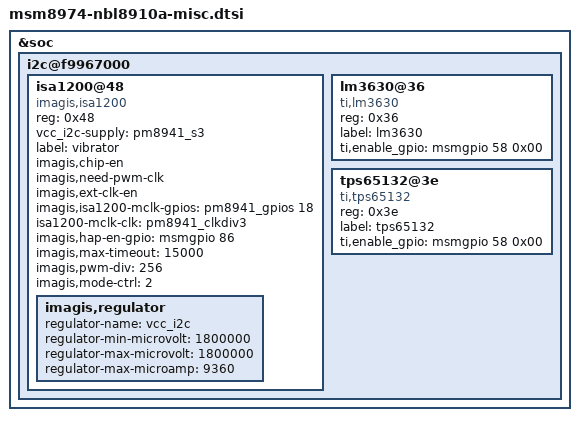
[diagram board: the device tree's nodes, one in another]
/* Copyright (c) 2018, The Linux Foundation. All rights reserved.
 *
 * This program is free software; you can redistribute it and/or modify
 * it under the terms of the GNU General Public License version 2 and
 * only version 2 as published by the Free Software Foundation.
 *
 * This program is distributed in the hope that it will be useful,
 * but WITHOUT ANY WARRANTY; without even the implied warranty of
 * MERCHANTABILITY or FITNESS FOR A PARTICULAR PURPOSE.  See the
 * GNU General Public License for more details.
 */

&soc {
	i2c@f9967000 {
		isa1200@48 {
			status = "okay";
			reg = <0x48>;
			vcc_i2c-supply = <&pm8941_s3>;
			compatible = "imagis,isa1200";
			label = "vibrator";
			imagis,chip-en;
			imagis,need-pwm-clk;
			imagis,ext-clk-en;
//GIONEE liujiang 2013-09-13 add for gpio-18 out 19.2M clk start
			imagis,isa1200-mclk-gpios = <&pm8941_gpios 18 0>;
			isa1200-mclk-clk = <&pm8941_clkdiv3>;
//GIONEE liujiang 2013-09-13 add for gpio-18 out 19.2M clk end
			imagis,hap-en-gpio = <&msmgpio 86 0x00>;
			imagis,max-timeout = <15000>;
			imagis,pwm-div = <256>;
			imagis,mode-ctrl = <2>;
			imagis,regulator {
				regulator-name = "vcc_i2c";
				regulator-min-microvolt = <1800000>;
				regulator-max-microvolt = <1800000>;
				regulator-max-microamp = <9360>;
			};
		};
		/*Gionee xiangzhong 2013-12-16  add for lm3630 begin*/
		lm3630@36 {
			status = "ok";
			reg = <0x36>;
			compatible = "ti,lm3630";
			label = "lm3630";
			ti,enable_gpio = <&msmgpio 58 0x00>;
		};
		/*Gionee xiangzhong 2013-12-16  add for lm3630 end*/
		//xiangzhong add for tps65132 begin
		tps65132@3e {
			status = "ok";
			reg = <0x3e>;
			compatible = "ti,tps65132";
			label = "tps65132";
			ti,enable_gpio = <&msmgpio 58 0x00>;
			};
		//xiangzhong add for tps65132 end
	};
};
